# PRM_GFX register map
Vendor: Texas Instruments
Peripheral module from a debugger description file (folder am335x).
Registers are 32-bit, access per field, no defined reset value unless marked. A register's access mark holds for its fields unless they carry their own. Offsets are as the file gives them; lines under a group give offsets from that group; [hi:lo] are bit positions; {n}, {i} and the like mark numbered series; 'fields as' and 'values as' point back to an identical list; <NAME> marks a mode.

## PRM_GFX
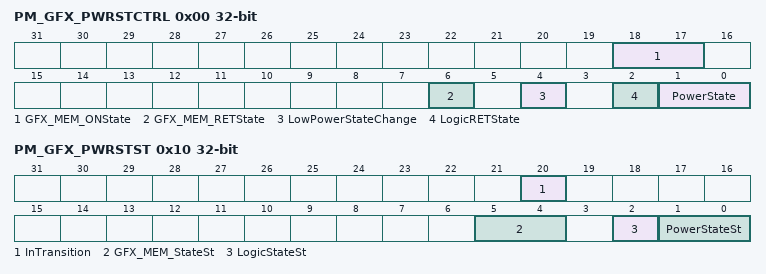
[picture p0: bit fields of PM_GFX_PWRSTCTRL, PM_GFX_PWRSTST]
0x00 PM_GFX_PWRSTCTRL — This register controls the GFX power state to reach upon a domain sleep transition.
  [18:17] GFX_MEM_ONState ro — GFX memory state when domain is ON.
    3=Mem_on (Memory bank is on when the domain is ON.)
  [6] GFX_MEM_RETState rw
    0=OFF (Memory is in off state); 1=RET (Memory is in retention state)
  [4] LowPowerStateChange rw — Power state change request when domain has already performed a sleep transition. Allows going into deeper low power state without waking up the power domain.
    0=DIS (Do not request a low power state change.); 1=EN (Request a low power state change. This bit is automatically cleared when the power state is effectively changed or when power state is ON.)
  [2] LogicRETState rw — Logic state when power domain is RETENTION
    0=logic_off (Only retention registers are retained and remaing logic is off when the domain is in RETENTION state.); 1=logic_ret (Whole logic is retained when domain is in RETENTION state.)
  [1:0] PowerState rw — Power state control
    0=OFF (OFF State); 1=RET; 3=ON (ON State)
0x04 RM_GFX_RSTCTRL — This register controls the release of the GFX Domain resets.
  [0] GFX_RST rw — GFX domain local reset control
    0=CLEAR (Reset is cleared for the GFX Domain (SGX530)); 1=ASSERT (Reset is asserted for the GFX Domain (SGX 530))
0x10 PM_GFX_PWRSTST ro — This register provides a status on the current GFX power domain state. [warm reset insensitive]
  [20] InTransition — Domain transition status
    0=No (No on-going transition on power domain); 1=Ongoing (Power domain transition is in progress.)
  [5:4] GFX_MEM_StateSt — GFX memory state status
    0=Mem_off (Memory is OFF); 3=Mem_on (Memory is ON)
  [2] LogicStateSt — Logic state status
    0=OFF (Logic in domain is OFF); 1=ON (Logic in domain is ON)
  [1:0] PowerStateSt — Current Power State Status
    0=OFF (OFF State [warm reset insensitive]); 1=RET; 3=ON (ON State [warm reset insensitive])
0x14 RM_GFX_RSTST — This register logs the different reset sources of the GFX domain. Each bit is set upon release of the domain reset signal. Must be cleared by software. [warm reset insensitive]
  [0] GFX_RST rw — GFX Domain Logic Reset
    0=RESET_NO (No SW reset occured); 1=RESET_YES (GFX Domain Logic has been reset upon SW reset)
